# ATSAM4LS8A register map
Vendor: Atmel Corporation; Series: SAM4L; File version: A
CPU: CM4 r0p1, little endian, MPU, no FPU, 4 interrupt priority bits
Registers are 32-bit, write-only, reset 0x0 unless marked. A register's access mark holds for its fields unless they carry their own. Offsets are from the block's base; [hi:lo] are bit positions.

## ADCIFE — ADC controller interface
Base 0x40038000; register names take the prefix ADCIFE_
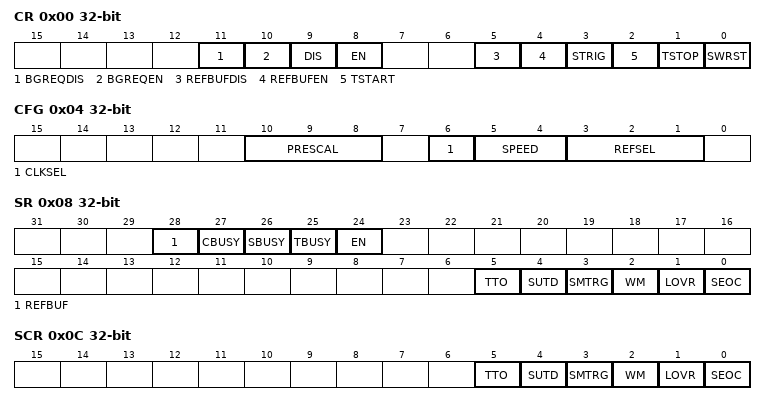
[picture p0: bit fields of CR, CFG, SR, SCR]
0x00 CR — Control Register
  [11] BGREQDIS — Bandgap buffer request disable
  [10] BGREQEN — Bandgap buffer request enable
  [9] DIS — ADCIFD disable
  [8] EN — ADCIFD enable
  [5] REFBUFDIS — Reference buffer disable
  [4] REFBUFEN — Reference buffer enable
  [3] STRIG — Sequencer trigger
  [2] TSTART — Internal timer start bit
  [1] TSTOP — Internal timer stop bit
  [0] SWRST — Software reset
0x04 CFG rw — Configuration Register
  [10:8] PRESCAL — Prescaler Rate Selection
  [6] CLKSEL — Clock Selection for sequencer/ADC cell
  [5:4] SPEED — ADC current reduction
  [3:1] REFSEL — ADC Reference Selection
0x08 SR ro — Status Register
  [28] REFBUF — Reference buffer status
  [27] CBUSY — Conversion busy
  [26] SBUSY — Sequencer busy
  [25] TBUSY — Timer busy
  [24] EN — Enable Status
  [5] TTO — Timer time-out
  [4] SUTD — Start-up time done
  [3] SMTRG — Sequencer missed trigger event
  [2] WM — Window monitor
  [1] LOVR — Sequencer last converted value overrun
  [0] SEOC — Sequencer end of conversion
0x0C SCR — Status Clear Register
  [5] TTO — Timer time-out
  [4] SUTD — Start-up time done
  [3] SMTRG — Sequencer missed trigger event
  [2] WM — Window monitor
  [1] LOVR — Sequencer last converted value overrun
  [0] SEOC — Sequencer end of conversion
0x10 RTS rw — Resistive Touch Screen Register
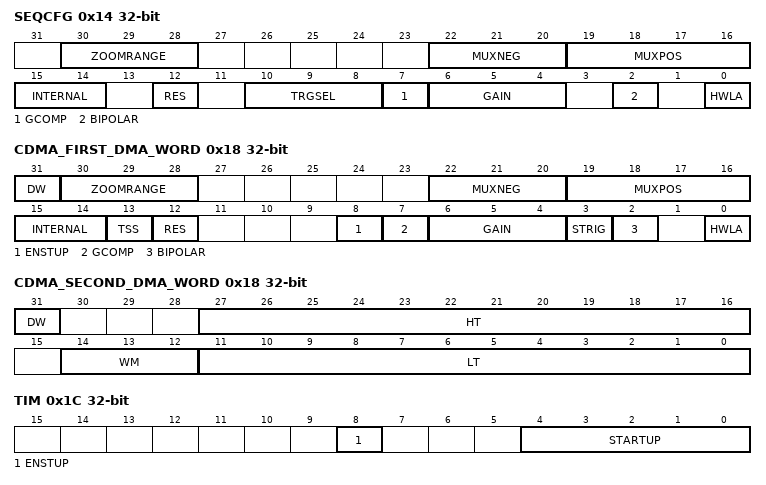
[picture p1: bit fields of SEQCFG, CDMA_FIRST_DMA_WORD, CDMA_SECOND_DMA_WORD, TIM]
0x14 SEQCFG rw — Sequencer Configuration Register
  [30:28] ZOOMRANGE — Zoom shift/unipolar reference source selection
  [22:20] MUXNEG — MUX selection on Negative ADC input channel
  [19:16] MUXPOS — MUX selection on Positive ADC input channel
  [15:14] INTERNAL — Internal Voltage Source Selection
  [12] RES — Resolution
  [10:8] TRGSEL — Trigger selection
  [7] GCOMP — Gain Compensation
  [6:4] GAIN — Gain factor
  [2] BIPOLAR — Bipolar Mode
  [0] HWLA — Half word left adjust
0x18 CDMA_FIRST_DMA_WORD (alternate view of CDMA) — Configuration Direct Memory Access Register
  [31] DW — Double Word transmitting
  [30:28] ZOOMRANGE — Zoom shift/unipolar reference source selection
  [22:20] MUXNEG — MUX selection on Negative ADC input channel
  [19:16] MUXPOS — MUX selection on Positive ADC input channel
  [15:14] INTERNAL — Internal Voltage Source Selection
  [13] TSS — Internal timer start or stop bit
  [12] RES — Resolution
  [8] ENSTUP — Enable Start-Up Time
  [7] GCOMP — Gain Compensation
  [6:4] GAIN — Gain factor
  [3] STRIG — Sequencer Trigger Event
  [2] BIPOLAR — Bipolar Mode
  [0] HWLA — Half word left adjust
0x18 CDMA_SECOND_DMA_WORD (alternate view of CDMA) — Configuration Direct Memory Access Register
  [31] DW — Double Word transmitting
  [27:16] HT — High Threshold
  [14:12] WM — Window Monitor Mode
  [11:0] LT — Low Threshold
0x1C TIM rw — Timing Configuration Register
  [8] ENSTUP — Enable Startup
  [4:0] STARTUP — Startup time
0x20 ITIMER rw — Internal Timer Register
  [15:0] ITMC — Internal timer max counter
0x24 WCFG rw — Window Monitor Configuration Register
  [14:12] WM — Window Monitor Mode
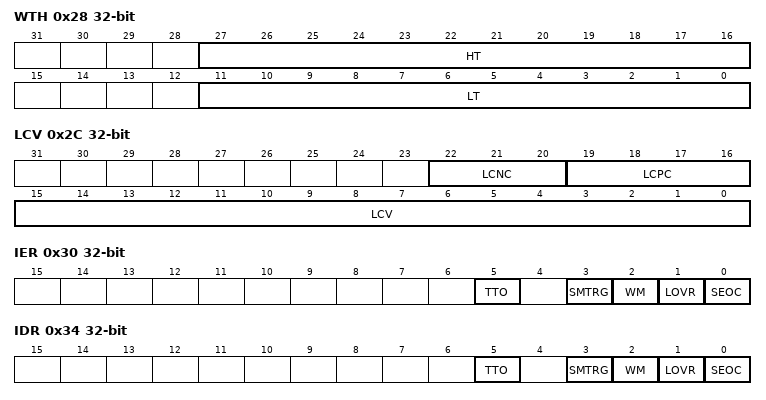
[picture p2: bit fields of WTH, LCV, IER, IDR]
0x28 WTH rw — Window Monitor Threshold Configuration Register
  [27:16] HT — High Threshold
  [11:0] LT — Low threshold
0x2C LCV ro — Sequencer Last Converted Value Register
  [22:20] LCNC — Last converted negative channel
  [19:16] LCPC — Last converted positive channel
  [15:0] LCV — Last converted value
0x30 IER — Interrupt Enable Register
  [5] TTO — Timer time-out Interrupt Enable
  [3] SMTRG — Sequencer missed trigger event Interrupt Enable
  [2] WM — Window monitor Interrupt Enable
  [1] LOVR — Sequencer last converted value overrun Interrupt Enable
  [0] SEOC — Sequencer end of conversion Interrupt Enable
0x34 IDR — Interrupt Disable Register
  [5] TTO — Timer time-out Interrupt Disable
  [3] SMTRG — Sequencer missed trigger event Interrupt Disable
  [2] WM — Window monitor Interrupt Disable
  [1] LOVR — Sequencer last converted value overrun Interrupt Disable
  [0] SEOC — Sequencer end of conversion Interrupt Disable
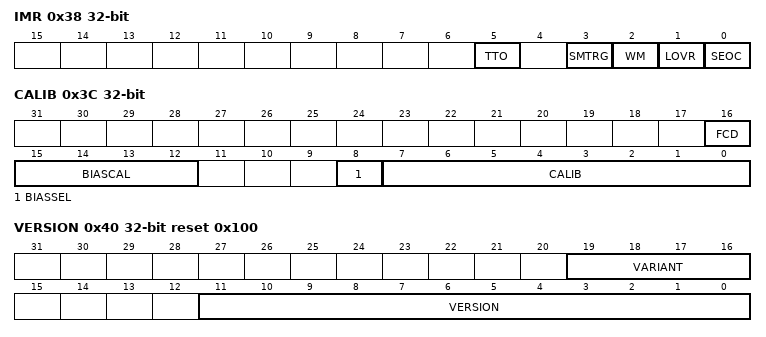
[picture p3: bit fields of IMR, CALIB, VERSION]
0x38 IMR ro — Interrupt Mask Register
  [5] TTO — Timer time-out Interrupt Mask
  [3] SMTRG — Sequencer missed trigger event Interrupt Mask
  [2] WM — Window monitor Interrupt Mask
  [1] LOVR — Sequencer last converted value overrun Interrupt Mask
  [0] SEOC — Sequencer end of conversion Interrupt Mask
0x3C CALIB rw — Calibration Register
  [16] FCD — Flash Calibration Done
  [15:12] BIASCAL — Bias Calibration
  [8] BIASSEL — Select bias mode
  [7:0] CALIB — Calibration Value
0x40 VERSION ro reset 0x100
  [19:16] VARIANT — Variant number
  [11:0] VERSION — Version number
0x44 PARAMETER ro
  [7:0] N — Number of channels

## Notices in the file
Atmel Microcontroller Software Support
Copyright (c) 2016 Atmel Corporation,
a wholly owned subsidiary of Microchip Technology Inc.
Licensed under the Apache License, Version 2.0 (the "License");
you may not use this file except in compliance with the License.
You may obtain a copy of the Licence at
http://www.apache.org/licenses/LICENSE-2.0
Unless required by applicable law or agreed to in writing, software
distributed under the License is distributed on an "AS IS" BASIS,
WITHOUT WARRANTIES OR CONDITIONS OF ANY KIND, either express or implied.
See the License for the specific language governing permissions and
limitations under the License.
